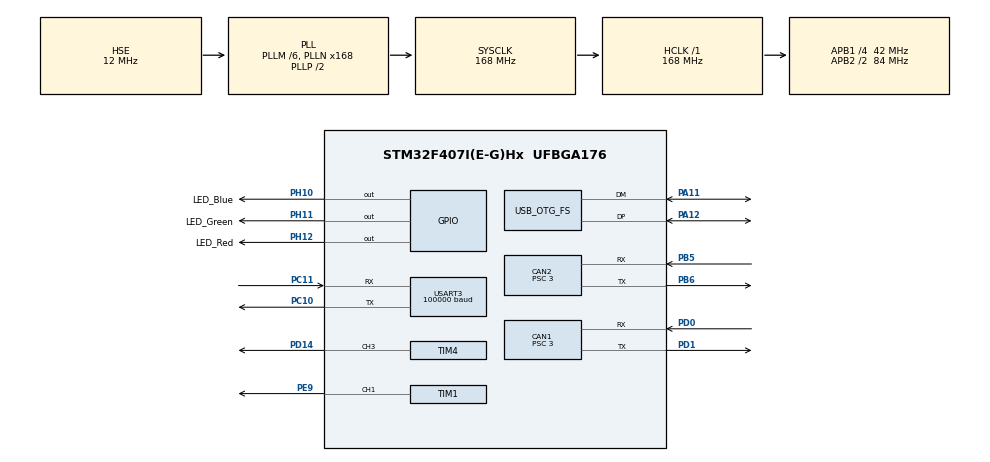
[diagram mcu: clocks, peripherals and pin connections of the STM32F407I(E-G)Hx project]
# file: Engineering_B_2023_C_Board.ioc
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CAN1.BS1=CAN_BS1_10TQ
CAN1.BS2=CAN_BS2_3TQ
CAN1.CalculateBaudRate=1000000
CAN1.CalculateTimeBit=1000
CAN1.CalculateTimeQuantum=71.42857142857143
CAN1.Prescaler=3
CAN2.ABOM=ENABLE
CAN2.AWUM=ENABLE
CAN2.BS1=CAN_BS1_10TQ
CAN2.BS2=CAN_BS2_3TQ
CAN2.CalculateBaudRate=1000000
CAN2.CalculateTimeBit=1000
CAN2.CalculateTimeQuantum=71.42857142857143
CAN2.Prescaler=3
Dma.Request0=USART3_RX
Dma.USART3_RX.0.Direction=DMA_PERIPH_TO_MEMORY
Dma.USART3_RX.0.FIFOMode=DMA_FIFOMODE_DISABLE
Dma.USART3_RX.0.Instance=DMA1_Stream1
Dma.USART3_RX.0.MemDataAlignment=DMA_MDATAALIGN_BYTE
Dma.USART3_RX.0.MemInc=DMA_MINC_ENABLE
Dma.USART3_RX.0.Mode=DMA_NORMAL
Dma.USART3_RX.0.PeriphDataAlignment=DMA_PDATAALIGN_BYTE
Dma.USART3_RX.0.PeriphInc=DMA_PINC_DISABLE
Dma.USART3_RX.0.Priority=DMA_PRIORITY_HIGH
FREERTOS.INCLUDE_eTaskGetState=1
FREERTOS.Tasks01=defaultTask,0,128,StartDefaultTask,Default,NULL,Dynamic,NULL,NULL;Task_Chassis,2,128,Chassis_Task,As external,NULL,Dynamic,NULL,NULL;Task_Remote,0,128,Remote_Task,As external,NULL,Dynamic,NULL,NULL;Task_Detect,-3,128,Detect_Task,As external,NULL,Dynamic,NULL,NULL
FREERTOS.configENABLE_FPU=0
FREERTOS.configUSE_NEWLIB_REENTRANT=0
Mcu.Family=STM32F4
Mcu.Name=STM32F407I(E-G)Hx
Mcu.Package=UFBGA176
NVIC.CAN1_RX0_IRQn=true\:5\:0\:false\:false\:true\:true\:true\:true\:true
NVIC.CAN1_TX_IRQn=true\:5\:0\:false\:false\:true\:true\:true\:true\:true
NVIC.CAN2_RX0_IRQn=true\:5\:0\:false\:false\:true\:true\:true\:true\:true
NVIC.CAN2_TX_IRQn=true\:5\:0\:false\:false\:true\:true\:true\:true\:true
NVIC.DMA1_Stream1_IRQn=true\:5\:0\:false\:false\:true\:true\:false\:true\:true
NVIC.OTG_FS_IRQn=true\:5\:0\:false\:false\:true\:true\:false\:true\:true
NVIC.PriorityGroup=NVIC_PRIORITYGROUP_4
NVIC.TIM2_IRQn=true\:15\:0\:false\:false\:true\:false\:false\:true\:true
NVIC.TimeBase=TIM2_IRQn
NVIC.TimeBaseIP=TIM2
NVIC.USART3_IRQn=true\:5\:0\:false\:false\:true\:true\:true\:true\:true
PA10.Signal=USB_OTG_FS_ID
PA11.Mode=Device_Only
PA11.Signal=USB_OTG_FS_DM
PA12.Mode=Device_Only
PA12.Signal=USB_OTG_FS_DP
PB5.Mode=CAN_Activate
PB5.Signal=CAN2_RX
PB6.Mode=CAN_Activate
PB6.Signal=CAN2_TX
PC10.Mode=Asynchronous
PC10.Signal=USART3_TX
PC11.Mode=Asynchronous
PC11.Signal=USART3_RX
PD0.Mode=CAN_Activate
PD0.Signal=CAN1_RX
PD1.Mode=CAN_Activate
PD1.Signal=CAN1_TX
PD14.Signal=S_TIM4_CH3
PE9.Signal=S_TIM1_CH1
PH0-OSC_IN.Mode=HSE-External-Oscillator
PH0-OSC_IN.Signal=RCC_OSC_IN
PH1-OSC_OUT.Mode=HSE-External-Oscillator
PH1-OSC_OUT.Signal=RCC_OSC_OUT
PH10.GPIO_Label=LED_Blue
PH10.GPIO_PuPd=GPIO_PULLUP
PH10.PinState=GPIO_PIN_SET
PH10.Signal=GPIO_Output
PH11.GPIO_Label=LED_Green
PH11.GPIO_PuPd=GPIO_PULLUP
PH11.PinState=GPIO_PIN_SET
PH11.Signal=GPIO_Output
PH12.GPIO_Label=LED_Red
PH12.GPIO_PuPd=GPIO_PULLUP
PH12.PinState=GPIO_PIN_SET
PH12.Signal=GPIO_Output
ProjectManager.HeapSize=0x2000
ProjectManager.StackSize=0x2000
ProjectManager.TargetToolchain=MDK-ARM V5.32
RCC.48MHZClocksFreq_Value=48000000
RCC.AHBFreq_Value=168000000
RCC.APB1CLKDivider=RCC_HCLK_DIV4
RCC.APB1Freq_Value=42000000
RCC.APB1TimFreq_Value=84000000
RCC.APB2CLKDivider=RCC_HCLK_DIV2
RCC.APB2Freq_Value=84000000
RCC.APB2TimFreq_Value=168000000
RCC.CortexFreq_Value=168000000
RCC.HCLKFreq_Value=168000000
RCC.HSE_VALUE=12000000
RCC.HSI_VALUE=16000000
RCC.LSE_VALUE=32768
RCC.PLLM=6
RCC.PLLN=168
RCC.PLLQ=7
RCC.SYSCLKFreq_VALUE=168000000
RCC.SYSCLKSource=RCC_SYSCLKSOURCE_PLLCLK
RCC.VCOOutputFreq_Value=336000000
SH.S_TIM1_CH1.0=TIM1_CH1,PWM Generation1 CH1
SH.S_TIM4_CH3.0=TIM4_CH3,PWM Generation3 CH3
STMicroelectronics.X-CUBE-ALGOBUILD.1.3.0.LibraryCcDSPOoLibraryJjDSPOoLibrary=true
TIM1.Channel-PWM\ Generation1\ CH1=TIM_CHANNEL_1
TIM1.Period=19999
TIM1.Prescaler=167
TIM1.Pulse-PWM\ Generation1\ CH1=2000
TIM4.Channel-PWM\ Generation3\ CH3=TIM_CHANNEL_3
TIM4.Period=20999
USART3.BaudRate=100000
USART3.Parity=PARITY_EVEN
USART3.VirtualMode=VM_ASYNC
USB_DEVICE.CLASS_NAME_FS=CDC
USB_DEVICE.VirtualMode-CDC_FS=Cdc
USB_DEVICE.VirtualModeFS=Cdc_FS
USB_OTG_FS.VirtualMode=Device_Only
VP_FREERTOS_VS_CMSIS_V1.Mode=CMSIS_V1
VP_STMicroelectronics.X-CUBE-ALGOBUILD_VS_DSPOoLibraryJjLibrary_1.3.0_1.3.0.Mode=DSPOoLibraryJjLibrary
VP_SYS_VS_tim2.Mode=TIM2
VP_TIM4_VS_ClockSourceINT.Mode=Internal
VP_USB_DEVICE_VS_USB_DEVICE_CDC_FS.Mode=CDC_FS
board=custom

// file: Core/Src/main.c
/* USER CODE BEGIN Header */
/**
  ******************************************************************************
  * @file           : main.c
  * @brief          : Main program body
  ******************************************************************************
  * @attention
  *
  * Copyright (c) 2023 STMicroelectronics.
  * All rights reserved.
  *
  * This software is licensed under terms that can be found in the LICENSE file
  * in the root directory of this software component.
  * If no LICENSE file comes with this software, it is provided AS-IS.
  *
  ******************************************************************************
  */
/* USER CODE END Header */
#include "main.h"
#include "cmsis_os.h"
#include "can.h"
#include "dma.h"
#include "tim.h"
#include "usart.h"
#include "usb_device.h"
#include "gpio.h"

/* USER CODE BEGIN Includes */
#include "SYSInit.h"
/* USER CODE END Includes */

void SystemClock_Config(void);
void MX_FREERTOS_Init(void);

int main(void)
{

  /* MCU Configuration--------------------------------------------------------*/

  /* Reset of all peripherals, Initializes the Flash interface and the Systick. */
  HAL_Init();

  /* Configure the system clock */
  SystemClock_Config();

  /* Initialize all configured peripherals */
  MX_GPIO_Init();
  MX_DMA_Init();
  MX_CAN1_Init();
  MX_CAN2_Init();
  MX_USART3_UART_Init();
  MX_TIM4_Init();
  MX_TIM1_Init();
  /* USER CODE BEGIN 2 */
	Sys_Init();
  /* USER CODE END 2 */

  /* Call init function for freertos objects (in freertos.c) */
  MX_FREERTOS_Init();

  /* Start scheduler */
  osKernelStart();

  /* We should never get here as control is now taken by the scheduler */
  /* Infinite loop */
  while (1)
  {

  }
}

void SystemClock_Config(void)
{
  RCC_OscInitTypeDef RCC_OscInitStruct = {0};
  RCC_ClkInitTypeDef RCC_ClkInitStruct = {0};

  /** Configure the main internal regulator output voltage
  */
  __HAL_RCC_PWR_CLK_ENABLE();
  __HAL_PWR_VOLTAGESCALING_CONFIG(PWR_REGULATOR_VOLTAGE_SCALE1);

  /** Initializes the RCC Oscillators according to the specified parameters
  * in the RCC_OscInitTypeDef structure.
  */
  RCC_OscInitStruct.OscillatorType = RCC_OSCILLATORTYPE_HSE;
  RCC_OscInitStruct.HSEState = RCC_HSE_ON;
  RCC_OscInitStruct.PLL.PLLState = RCC_PLL_ON;
  RCC_OscInitStruct.PLL.PLLSource = RCC_PLLSOURCE_HSE;
  RCC_OscInitStruct.PLL.PLLM = 6;
  RCC_OscInitStruct.PLL.PLLN = 168;
  RCC_OscInitStruct.PLL.PLLP = RCC_PLLP_DIV2;
  RCC_OscInitStruct.PLL.PLLQ = 7;
  if (HAL_RCC_OscConfig(&RCC_OscInitStruct) != HAL_OK)
  {
    Error_Handler();
  }

  /** Initializes the CPU, AHB and APB buses clocks
  */
  RCC_ClkInitStruct.ClockType = RCC_CLOCKTYPE_HCLK|RCC_CLOCKTYPE_SYSCLK
                              |RCC_CLOCKTYPE_PCLK1|RCC_CLOCKTYPE_PCLK2;
  RCC_ClkInitStruct.SYSCLKSource = RCC_SYSCLKSOURCE_PLLCLK;
  RCC_ClkInitStruct.AHBCLKDivider = RCC_SYSCLK_DIV1;
  RCC_ClkInitStruct.APB1CLKDivider = RCC_HCLK_DIV4;
  RCC_ClkInitStruct.APB2CLKDivider = RCC_HCLK_DIV2;

  if (HAL_RCC_ClockConfig(&RCC_ClkInitStruct, FLASH_LATENCY_5) != HAL_OK)
  {
    Error_Handler();
  }
}

void HAL_TIM_PeriodElapsedCallback(TIM_HandleTypeDef *htim)
{
  if (htim->Instance == TIM2) {
    HAL_IncTick();
  }
}

void Error_Handler(void)
{
  __disable_irq();
  while (1)
  {
  }
}

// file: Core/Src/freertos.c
/* USER CODE BEGIN Header */
/**
  ******************************************************************************
  * File Name          : freertos.c
  * Description        : Code for freertos applications
  ******************************************************************************
  * @attention
  *
  * Copyright (c) 2023 STMicroelectronics.
  * All rights reserved.
  *
  * This software is licensed under terms that can be found in the LICENSE file
  * in the root directory of this software component.
  * If no LICENSE file comes with this software, it is provided AS-IS.
  *
  ******************************************************************************
  */
/* USER CODE END Header */

#include "FreeRTOS.h"
#include "task.h"
#include "main.h"
#include "cmsis_os.h"

osThreadId defaultTaskHandle;
osThreadId Task_ChassisHandle;
osThreadId Task_RemoteHandle;
osThreadId Task_DetectHandle;

void StartDefaultTask(void const * argument);
extern void Chassis_Task(void const * argument);
extern void Remote_Task(void const * argument);
extern void Detect_Task(void const * argument);

extern void MX_USB_DEVICE_Init(void);
void MX_FREERTOS_Init(void); /* (MISRA C 2004 rule 8.1) */

/* GetIdleTaskMemory prototype (linked to static allocation support) */
void vApplicationGetIdleTaskMemory( StaticTask_t **ppxIdleTaskTCBBuffer, StackType_t **ppxIdleTaskStackBuffer, uint32_t *pulIdleTaskStackSize );

/* USER CODE BEGIN GET_IDLE_TASK_MEMORY */
static StaticTask_t xIdleTaskTCBBuffer;
static StackType_t xIdleStack[configMINIMAL_STACK_SIZE];

void vApplicationGetIdleTaskMemory( StaticTask_t **ppxIdleTaskTCBBuffer, StackType_t **ppxIdleTaskStackBuffer, uint32_t *pulIdleTaskStackSize )
{
  *ppxIdleTaskTCBBuffer = &xIdleTaskTCBBuffer;
  *ppxIdleTaskStackBuffer = &xIdleStack[0];
  *pulIdleTaskStackSize = configMINIMAL_STACK_SIZE;
  /* place for user code */
}
/* USER CODE END GET_IDLE_TASK_MEMORY */

void MX_FREERTOS_Init(void) {

  /* Create the thread(s) */
  /* definition and creation of defaultTask */
  osThreadDef(defaultTask, StartDefaultTask, osPriorityNormal, 0, 128);
  defaultTaskHandle = osThreadCreate(osThread(defaultTask), NULL);

  /* definition and creation of Task_Chassis */
  osThreadDef(Task_Chassis, Chassis_Task, osPriorityHigh, 0, 128);
  Task_ChassisHandle = osThreadCreate(osThread(Task_Chassis), NULL);

  /* definition and creation of Task_Remote */
  osThreadDef(Task_Remote, Remote_Task, osPriorityNormal, 0, 128);
  Task_RemoteHandle = osThreadCreate(osThread(Task_Remote), NULL);

  /* definition and creation of Task_Detect */
  osThreadDef(Task_Detect, Detect_Task, osPriorityIdle, 0, 128);
  Task_DetectHandle = osThreadCreate(osThread(Task_Detect), NULL);

}

void StartDefaultTask(void const * argument)
{
  /* init code for USB_DEVICE */
  MX_USB_DEVICE_Init();
  for(;;)
  {
    osDelay(1);
  }
}
